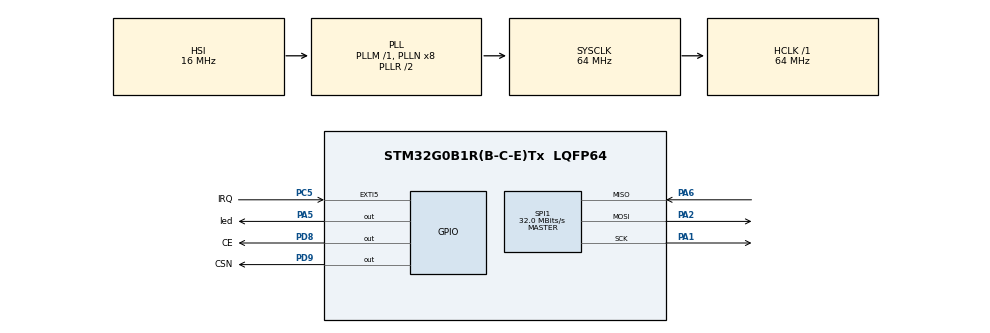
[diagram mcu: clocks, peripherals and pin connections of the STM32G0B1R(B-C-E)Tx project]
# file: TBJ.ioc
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Mcu.Family=STM32G0
Mcu.Name=STM32G0B1R(B-C-E)Tx
Mcu.Package=LQFP64
NVIC.SPI1_IRQn=true\:0\:0\:false\:false\:true\:true\:true
PA1.Mode=Full_Duplex_Master
PA1.Signal=SPI1_SCK
PA13.Mode=Serial_Wire
PA13.Signal=SYS_SWDIO
PA14-BOOT0.Mode=Serial_Wire
PA14-BOOT0.Signal=SYS_SWCLK
PA2.Mode=Full_Duplex_Master
PA2.Signal=SPI1_MOSI
PA5.GPIO_Label=led
PA5.Signal=GPIO_Output
PA6.Mode=Full_Duplex_Master
PA6.Signal=SPI1_MISO
PC5.GPIO_Label=IRQ
PC5.Signal=GPXTI5
PD8.GPIO_Label=CE
PD8.GPIO_Speed=GPIO_SPEED_FREQ_VERY_HIGH
PD8.Signal=GPIO_Output
PD9.GPIO_Label=CSN
PD9.GPIO_Speed=GPIO_SPEED_FREQ_VERY_HIGH
PD9.Signal=GPIO_Output
ProjectManager.HeapSize=0x200
ProjectManager.StackSize=0x400
ProjectManager.TargetToolchain=STM32CubeIDE
RCC.ADCFreq_Value=64000000
RCC.AHBFreq_Value=64000000
RCC.CortexFreq_Value=64000000
RCC.EXTERNAL_CLOCK_VALUE=48000
RCC.HCLKFreq_Value=64000000
RCC.HSE_VALUE=8000000
RCC.HSI48_VALUE=48000000
RCC.HSI_VALUE=16000000
RCC.LSE_VALUE=32768
RCC.SYSCLKFreq_VALUE=64000000
RCC.SYSCLKSource=RCC_SYSCLKSOURCE_PLLCLK
RCC.USBFreq_Value=48000000
RCC.VCOOutputFreq_Value=128000000
SPI1.CalculateBaudRate=32.0 MBits/s
SPI1.Direction=SPI_DIRECTION_2LINES
SPI1.Mode=SPI_MODE_MASTER
SPI1.VirtualType=VM_MASTER
VP_SYS_VS_DBSignals.Mode=DisableDeadBatterySignals
board=custom

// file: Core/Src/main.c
/* USER CODE BEGIN Header */
/**
  ******************************************************************************
  * @file           : main.c
  * @brief          : Main program body
  ******************************************************************************
  * @attention
  *
  * Copyright (c) 2022 STMicroelectronics.
  * All rights reserved.
  *
  * This software is licensed under terms that can be found in the LICENSE file
  * in the root directory of this software component.
  * If no LICENSE file comes with this software, it is provided AS-IS.
  *
  ******************************************************************************
  */
/* USER CODE END Header */
#include "main.h"

/* USER CODE BEGIN Includes */
#include "app.h"
/* USER CODE END Includes */

SPI_HandleTypeDef hspi1;

/* USER CODE BEGIN PV */
uint8_t data_array[4];
/* USER CODE END PV */

void SystemClock_Config(void);
static void MX_GPIO_Init(void);
static void MX_SPI1_Init(void);

int main(void)
{

  /* MCU Configuration--------------------------------------------------------*/

  /* Reset of all peripherals, Initializes the Flash interface and the Systick. */
  HAL_Init();

  /* Configure the system clock */
  SystemClock_Config();

  /* Initialize all configured peripherals */
  MX_GPIO_Init();
  MX_SPI1_Init();
  /* USER CODE BEGIN 2 */
  app_init();

  app_run();

  /* USER CODE END 2 */

  /* Infinite loop */
  while (1)
  {

  }
}

void SystemClock_Config(void)
{
  RCC_OscInitTypeDef RCC_OscInitStruct = {0};
  RCC_ClkInitTypeDef RCC_ClkInitStruct = {0};

  /** Configure the main internal regulator output voltage
  */
  HAL_PWREx_ControlVoltageScaling(PWR_REGULATOR_VOLTAGE_SCALE1);
  /** Initializes the RCC Oscillators according to the specified parameters
  * in the RCC_OscInitTypeDef structure.
  */
  RCC_OscInitStruct.OscillatorType = RCC_OSCILLATORTYPE_HSI;
  RCC_OscInitStruct.HSIState = RCC_HSI_ON;
  RCC_OscInitStruct.HSIDiv = RCC_HSI_DIV1;
  RCC_OscInitStruct.HSICalibrationValue = RCC_HSICALIBRATION_DEFAULT;
  RCC_OscInitStruct.PLL.PLLState = RCC_PLL_ON;
  RCC_OscInitStruct.PLL.PLLSource = RCC_PLLSOURCE_HSI;
  RCC_OscInitStruct.PLL.PLLM = RCC_PLLM_DIV1;
  RCC_OscInitStruct.PLL.PLLN = 8;
  RCC_OscInitStruct.PLL.PLLP = RCC_PLLP_DIV2;
  RCC_OscInitStruct.PLL.PLLQ = RCC_PLLQ_DIV2;
  RCC_OscInitStruct.PLL.PLLR = RCC_PLLR_DIV2;
  if (HAL_RCC_OscConfig(&RCC_OscInitStruct) != HAL_OK)
  {
    Error_Handler();
  }
  /** Initializes the CPU, AHB and APB buses clocks
  */
  RCC_ClkInitStruct.ClockType = RCC_CLOCKTYPE_HCLK|RCC_CLOCKTYPE_SYSCLK
                              |RCC_CLOCKTYPE_PCLK1;
  RCC_ClkInitStruct.SYSCLKSource = RCC_SYSCLKSOURCE_PLLCLK;
  RCC_ClkInitStruct.AHBCLKDivider = RCC_SYSCLK_DIV1;
  RCC_ClkInitStruct.APB1CLKDivider = RCC_HCLK_DIV1;

  if (HAL_RCC_ClockConfig(&RCC_ClkInitStruct, FLASH_LATENCY_2) != HAL_OK)
  {
    Error_Handler();
  }
}

static void MX_SPI1_Init(void)
{

  /* SPI1 parameter configuration*/
  hspi1.Instance = SPI1;
  hspi1.Init.Mode = SPI_MODE_MASTER;
  hspi1.Init.Direction = SPI_DIRECTION_2LINES;
  hspi1.Init.DataSize = SPI_DATASIZE_8BIT;
  hspi1.Init.CLKPolarity = SPI_POLARITY_LOW;
  hspi1.Init.CLKPhase = SPI_PHASE_1EDGE;
  hspi1.Init.NSS = SPI_NSS_SOFT;
  hspi1.Init.BaudRatePrescaler = SPI_BAUDRATEPRESCALER_2;
  hspi1.Init.FirstBit = SPI_FIRSTBIT_MSB;
  hspi1.Init.TIMode = SPI_TIMODE_DISABLE;
  hspi1.Init.CRCCalculation = SPI_CRCCALCULATION_DISABLE;
  hspi1.Init.CRCPolynomial = 7;
  hspi1.Init.CRCLength = SPI_CRC_LENGTH_DATASIZE;
  hspi1.Init.NSSPMode = SPI_NSS_PULSE_ENABLE;
  if (HAL_SPI_Init(&hspi1) != HAL_OK)
  {
    Error_Handler();
  }

}

static void MX_GPIO_Init(void)
{
  GPIO_InitTypeDef GPIO_InitStruct = {0};

  /* GPIO Ports Clock Enable */
  __HAL_RCC_GPIOA_CLK_ENABLE();
  __HAL_RCC_GPIOC_CLK_ENABLE();
  __HAL_RCC_GPIOD_CLK_ENABLE();

  /*Configure GPIO pin Output Level */
  HAL_GPIO_WritePin(led_GPIO_Port, led_Pin, GPIO_PIN_RESET);

  /*Configure GPIO pin Output Level */
  HAL_GPIO_WritePin(GPIOD, CE_Pin|CSN_Pin, GPIO_PIN_RESET);

  /*Configure GPIO pin : led_Pin */
  GPIO_InitStruct.Pin = led_Pin;
  GPIO_InitStruct.Mode = GPIO_MODE_OUTPUT_PP;
  GPIO_InitStruct.Pull = GPIO_NOPULL;
  GPIO_InitStruct.Speed = GPIO_SPEED_FREQ_LOW;
  HAL_GPIO_Init(led_GPIO_Port, &GPIO_InitStruct);

  /*Configure GPIO pin : IRQ_Pin */
  GPIO_InitStruct.Pin = IRQ_Pin;
  GPIO_InitStruct.Mode = GPIO_MODE_IT_RISING;
  GPIO_InitStruct.Pull = GPIO_NOPULL;
  HAL_GPIO_Init(IRQ_GPIO_Port, &GPIO_InitStruct);

  /*Configure GPIO pins : CE_Pin CSN_Pin */
  GPIO_InitStruct.Pin = CE_Pin|CSN_Pin;
  GPIO_InitStruct.Mode = GPIO_MODE_OUTPUT_PP;
  GPIO_InitStruct.Pull = GPIO_NOPULL;
  GPIO_InitStruct.Speed = GPIO_SPEED_FREQ_VERY_HIGH;
  HAL_GPIO_Init(GPIOD, &GPIO_InitStruct);

}

void Error_Handler(void)
{
  __disable_irq();
  while (1)
  {
  }
}
